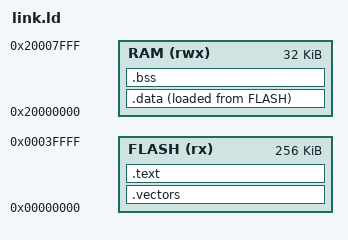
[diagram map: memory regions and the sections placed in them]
/* V85XXP link-check memory map, derived from V85XX_flash.icf. */
ENTRY(Reset_Handler)

MEMORY
{
    FLASH (rx)  : ORIGIN = 0x00000000, LENGTH = 256K
    RAM   (rwx) : ORIGIN = 0x20000000, LENGTH = 32K
}

_estack = ORIGIN(RAM) + LENGTH(RAM);
CSTACK$$Base = ORIGIN(RAM);
CSTACK$$Limit = _estack;

SECTIONS
{
    .vectors : {
        KEEP(*(.vectors))
    } > FLASH

    .text : {
        *(.text*)
        *(.rodata*)
    } > FLASH

    .data : {
        _sdata = .;
        *(.data*)
        _edata = .;
    } > RAM AT> FLASH
    _sidata = LOADADDR(.data);

    .bss : {
        _sbss = .;
        *(.bss*)
        *(COMMON)
        _ebss = .;
    } > RAM
}
